# RX64M_RIIC_Pilot register map
File version: 1.0
RX64M_RIIC_Pilot peripheral registers generated from iodefine.h (pilot).
Registers are 8-bit, read-write, reset 0x0 unless marked. A register's access mark holds for its fields unless they carry their own. Offsets are from the block's base; lines under a group give offsets from that group; [hi:lo] are bit positions; {n}, {i} and the like mark numbered series; 'fields as' and 'values as' point back to an identical list; <NAME> marks a mode.

## Memory map
0x00088300 RIIC0 size 0x14
0x00088340 RIIC2 size 0x14

## RIIC0
Base 0x00088300
Same registers: RIIC2 0x00088340
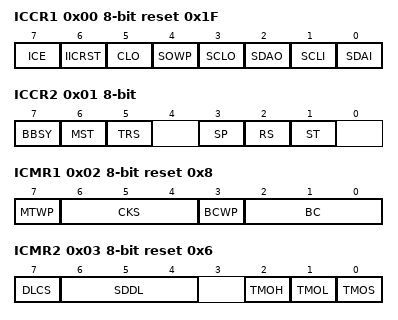
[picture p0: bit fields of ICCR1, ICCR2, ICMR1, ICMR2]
0x00 ICCR1 reset 0x1F
  [7] ICE, [6] IICRST, [5] CLO, [4] SOWP, [3] SCLO, [2] SDAO, [1] SCLI, [0] SDAI
0x01 ICCR2
  [7] BBSY, [6] MST, [5] TRS, [3] SP, [2] RS, [1] ST
0x02 ICMR1 reset 0x8
  [7] MTWP, [6:4] CKS, [3] BCWP, [2:0] BC
0x03 ICMR2 reset 0x6
  [7] DLCS, [6:4] SDDL, [2] TMOH, [1] TMOL, [0] TMOS
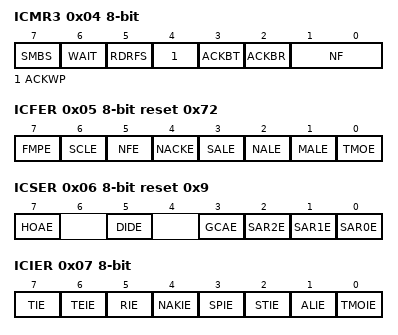
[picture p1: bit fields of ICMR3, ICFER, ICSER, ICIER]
0x04 ICMR3
  [7] SMBS, [6] WAIT, [5] RDRFS, [4] ACKWP, [3] ACKBT, [2] ACKBR, [1:0] NF
0x05 ICFER reset 0x72
  [7] FMPE, [6] SCLE, [5] NFE, [4] NACKE, [3] SALE, [2] NALE, [1] MALE, [0] TMOE
0x06 ICSER reset 0x9
  [7] HOAE, [5] DIDE, [3] GCAE, [2] SAR2E, [1] SAR1E, [0] SAR0E
0x07 ICIER
  [7] TIE, [6] TEIE, [5] RIE, [4] NAKIE, [3] SPIE, [2] STIE, [1] ALIE, [0] TMOIE
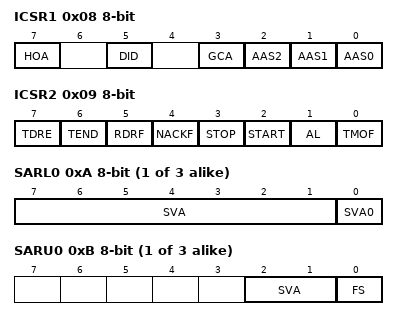
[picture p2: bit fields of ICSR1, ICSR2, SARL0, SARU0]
0x08 ICSR1
  [7] HOA, [5] DID, [3] GCA, [2] AAS2, [1] AAS1, [0] AAS0
0x09 ICSR2
  [7] TDRE, [6] TEND, [5] RDRF, [4] NACKF, [3] STOP, [2] START, [1] AL, [0] TMOF
{0xA+2i} SARL{i} (i=0..2)
  [7:1] SVA, [0] SVA0
{0xB+2i} SARU{i} (i=0..2)
  [2:1] SVA, [0] FS
0x10 ICBRL reset 0xFF
  [4:0] BRL
0x11 ICBRH reset 0xFF
  [4:0] BRH
0x12 ICDRT reset 0xFF
0x13 ICDRR ro
